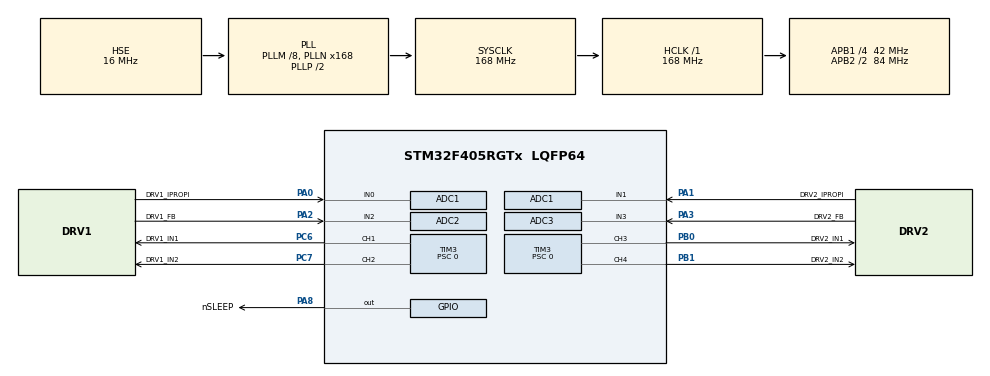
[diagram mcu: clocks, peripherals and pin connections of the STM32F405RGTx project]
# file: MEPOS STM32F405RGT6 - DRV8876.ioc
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ADC1.Channel-2\#ChannelRegularConversion=ADC_CHANNEL_0
ADC1.ClockPrescaler=ADC_CLOCK_SYNC_PCLK_DIV4
ADC1.NbrOfConversionFlag=1
ADC1.Rank-2\#ChannelRegularConversion=1
ADC1.SamplingTime-2\#ChannelRegularConversion=ADC_SAMPLETIME_3CYCLES
ADC1.master=1
ADC2.Channel-3\#ChannelRegularConversion=ADC_CHANNEL_2
ADC2.NbrOfConversionFlag=1
ADC2.Rank-3\#ChannelRegularConversion=1
ADC2.SamplingTime-3\#ChannelRegularConversion=ADC_SAMPLETIME_3CYCLES
ADC3.Channel-2\#ChannelRegularConversion=ADC_CHANNEL_3
ADC3.NbrOfConversionFlag=1
ADC3.Rank-2\#ChannelRegularConversion=1
ADC3.SamplingTime-2\#ChannelRegularConversion=ADC_SAMPLETIME_3CYCLES
Dma.ADC1.0.Direction=DMA_PERIPH_TO_MEMORY
Dma.ADC1.0.FIFOMode=DMA_FIFOMODE_DISABLE
Dma.ADC1.0.Instance=DMA2_Stream0
Dma.ADC1.0.MemDataAlignment=DMA_MDATAALIGN_HALFWORD
Dma.ADC1.0.MemInc=DMA_MINC_ENABLE
Dma.ADC1.0.Mode=DMA_CIRCULAR
Dma.ADC1.0.PeriphDataAlignment=DMA_PDATAALIGN_HALFWORD
Dma.ADC1.0.PeriphInc=DMA_PINC_DISABLE
Dma.ADC1.0.Priority=DMA_PRIORITY_LOW
Dma.ADC2.6.Direction=DMA_PERIPH_TO_MEMORY
Dma.ADC2.6.FIFOMode=DMA_FIFOMODE_DISABLE
Dma.ADC2.6.Instance=DMA2_Stream2
Dma.ADC2.6.MemDataAlignment=DMA_MDATAALIGN_HALFWORD
Dma.ADC2.6.MemInc=DMA_MINC_ENABLE
Dma.ADC2.6.Mode=DMA_CIRCULAR
Dma.ADC2.6.PeriphDataAlignment=DMA_PDATAALIGN_HALFWORD
Dma.ADC2.6.PeriphInc=DMA_PINC_DISABLE
Dma.ADC2.6.Priority=DMA_PRIORITY_LOW
Dma.ADC3.5.Direction=DMA_PERIPH_TO_MEMORY
Dma.ADC3.5.FIFOMode=DMA_FIFOMODE_DISABLE
Dma.ADC3.5.Instance=DMA2_Stream1
Dma.ADC3.5.MemDataAlignment=DMA_MDATAALIGN_HALFWORD
Dma.ADC3.5.MemInc=DMA_MINC_ENABLE
Dma.ADC3.5.Mode=DMA_CIRCULAR
Dma.ADC3.5.PeriphDataAlignment=DMA_PDATAALIGN_HALFWORD
Dma.ADC3.5.PeriphInc=DMA_PINC_DISABLE
Dma.ADC3.5.Priority=DMA_PRIORITY_LOW
Dma.Request0=ADC1
Dma.Request1=TIM3_CH1/TRIG
Dma.Request2=TIM3_CH2
Dma.Request3=TIM3_CH3
Dma.Request4=TIM3_CH4/UP
Dma.Request5=ADC3
Dma.Request6=ADC2
Dma.TIM3_CH1/TRIG.1.Direction=DMA_PERIPH_TO_MEMORY
Dma.TIM3_CH1/TRIG.1.FIFOMode=DMA_FIFOMODE_DISABLE
Dma.TIM3_CH1/TRIG.1.Instance=DMA1_Stream4
Dma.TIM3_CH1/TRIG.1.MemDataAlignment=DMA_MDATAALIGN_HALFWORD
Dma.TIM3_CH1/TRIG.1.MemInc=DMA_MINC_ENABLE
Dma.TIM3_CH1/TRIG.1.Mode=DMA_CIRCULAR
Dma.TIM3_CH1/TRIG.1.PeriphDataAlignment=DMA_PDATAALIGN_HALFWORD
Dma.TIM3_CH1/TRIG.1.PeriphInc=DMA_PINC_DISABLE
Dma.TIM3_CH1/TRIG.1.Priority=DMA_PRIORITY_LOW
Dma.TIM3_CH2.2.Direction=DMA_PERIPH_TO_MEMORY
Dma.TIM3_CH2.2.FIFOMode=DMA_FIFOMODE_DISABLE
Dma.TIM3_CH2.2.Instance=DMA1_Stream5
Dma.TIM3_CH2.2.MemDataAlignment=DMA_MDATAALIGN_HALFWORD
Dma.TIM3_CH2.2.MemInc=DMA_MINC_ENABLE
Dma.TIM3_CH2.2.Mode=DMA_CIRCULAR
Dma.TIM3_CH2.2.PeriphDataAlignment=DMA_PDATAALIGN_HALFWORD
Dma.TIM3_CH2.2.PeriphInc=DMA_PINC_DISABLE
Dma.TIM3_CH2.2.Priority=DMA_PRIORITY_LOW
Dma.TIM3_CH3.3.Direction=DMA_PERIPH_TO_MEMORY
Dma.TIM3_CH3.3.FIFOMode=DMA_FIFOMODE_DISABLE
Dma.TIM3_CH3.3.Instance=DMA1_Stream7
Dma.TIM3_CH3.3.MemDataAlignment=DMA_MDATAALIGN_HALFWORD
Dma.TIM3_CH3.3.MemInc=DMA_MINC_ENABLE
Dma.TIM3_CH3.3.Mode=DMA_CIRCULAR
Dma.TIM3_CH3.3.PeriphDataAlignment=DMA_PDATAALIGN_HALFWORD
Dma.TIM3_CH3.3.PeriphInc=DMA_PINC_DISABLE
Dma.TIM3_CH3.3.Priority=DMA_PRIORITY_LOW
Dma.TIM3_CH4/UP.4.Direction=DMA_PERIPH_TO_MEMORY
Dma.TIM3_CH4/UP.4.FIFOMode=DMA_FIFOMODE_DISABLE
Dma.TIM3_CH4/UP.4.Instance=DMA1_Stream2
Dma.TIM3_CH4/UP.4.MemDataAlignment=DMA_MDATAALIGN_HALFWORD
Dma.TIM3_CH4/UP.4.MemInc=DMA_MINC_ENABLE
Dma.TIM3_CH4/UP.4.Mode=DMA_CIRCULAR
Dma.TIM3_CH4/UP.4.PeriphDataAlignment=DMA_PDATAALIGN_HALFWORD
Dma.TIM3_CH4/UP.4.PeriphInc=DMA_PINC_DISABLE
Dma.TIM3_CH4/UP.4.Priority=DMA_PRIORITY_LOW
Mcu.Family=STM32F4
Mcu.Name=STM32F405RGTx
Mcu.Package=LQFP64
NVIC.ADC_IRQn=true\:0\:0\:false\:false\:true\:true\:true\:true
NVIC.DMA1_Stream2_IRQn=true\:0\:0\:false\:false\:true\:false\:true\:true
NVIC.DMA1_Stream4_IRQn=true\:0\:0\:false\:false\:true\:false\:true\:true
NVIC.DMA1_Stream5_IRQn=true\:0\:0\:false\:false\:true\:false\:true\:true
NVIC.DMA1_Stream7_IRQn=true\:0\:0\:false\:false\:true\:false\:true\:true
NVIC.DMA2_Stream0_IRQn=true\:0\:0\:false\:false\:true\:false\:true\:true
NVIC.DMA2_Stream1_IRQn=true\:0\:0\:false\:false\:true\:false\:true\:true
NVIC.DMA2_Stream2_IRQn=true\:0\:0\:false\:false\:true\:false\:true\:true
NVIC.PriorityGroup=NVIC_PRIORITYGROUP_4
NVIC.TIM3_IRQn=true\:0\:0\:false\:false\:true\:true\:true\:true
PA0-WKUP.GPIO_Label=DRV1_IPROPI
PA0-WKUP.Signal=ADCx_IN0
PA1.GPIO_Label=DRV2_IPROPI
PA1.Signal=ADCx_IN1
PA13.Mode=Serial_Wire
PA13.Signal=SYS_JTMS-SWDIO
PA14.Mode=Serial_Wire
PA14.Signal=SYS_JTCK-SWCLK
PA2.GPIO_Label=DRV1_FB
PA2.Signal=ADCx_IN2
PA3.GPIO_Label=DRV2_FB
PA3.Signal=ADCx_IN3
PA8.GPIO_Label=nSLEEP
PA8.Signal=GPIO_Output
PB0.GPIO_Label=DRV2_IN1
PB0.Signal=S_TIM3_CH3
PB1.GPIO_Label=DRV2_IN2
PB1.Signal=S_TIM3_CH4
PC6.GPIO_Label=DRV1_IN1
PC6.Signal=S_TIM3_CH1
PC7.GPIO_Label=DRV1_IN2
PC7.Signal=S_TIM3_CH2
PH0-OSC_IN.Mode=HSE-External-Oscillator
PH0-OSC_IN.Signal=RCC_OSC_IN
PH1-OSC_OUT.Mode=HSE-External-Oscillator
PH1-OSC_OUT.Signal=RCC_OSC_OUT
ProjectManager.HeapSize=0x200
ProjectManager.StackSize=0x400
ProjectManager.TargetToolchain=STM32CubeIDE
RCC.48MHZClocksFreq_Value=48000000
RCC.AHBFreq_Value=168000000
RCC.APB1CLKDivider=RCC_HCLK_DIV4
RCC.APB1Freq_Value=42000000
RCC.APB1TimFreq_Value=84000000
RCC.APB2CLKDivider=RCC_HCLK_DIV2
RCC.APB2Freq_Value=84000000
RCC.APB2TimFreq_Value=168000000
RCC.CortexFreq_Value=168000000
RCC.HCLKFreq_Value=168000000
RCC.HSE_VALUE=16000000
RCC.HSI_VALUE=16000000
RCC.LSE_VALUE=32768
RCC.PLLM=8
RCC.PLLN=168
RCC.PLLQ=7
RCC.PLLSourceVirtual=RCC_PLLSOURCE_HSE
RCC.SYSCLKFreq_VALUE=168000000
RCC.SYSCLKSource=RCC_SYSCLKSOURCE_PLLCLK
RCC.VCOOutputFreq_Value=336000000
SH.ADCx_IN0.0=ADC1_IN0,IN0
SH.ADCx_IN1.0=ADC1_IN1,IN1
SH.ADCx_IN2.0=ADC2_IN2,IN2
SH.ADCx_IN3.0=ADC3_IN3,IN3
SH.S_TIM3_CH1.0=TIM3_CH1,PWM Generation1 CH1
SH.S_TIM3_CH2.0=TIM3_CH2,PWM Generation2 CH2
SH.S_TIM3_CH3.0=TIM3_CH3,PWM Generation3 CH3
SH.S_TIM3_CH4.0=TIM3_CH4,PWM Generation4 CH4
TIM3.Channel-PWM\ Generation1\ CH1=TIM_CHANNEL_1
TIM3.Channel-PWM\ Generation2\ CH2=TIM_CHANNEL_2
TIM3.Channel-PWM\ Generation3\ CH3=TIM_CHANNEL_3
TIM3.Channel-PWM\ Generation4\ CH4=TIM_CHANNEL_4
TIM3.Period=8400-1
TIM3.Prescaler=0
VP_TIM3_VS_ClockSourceINT.Mode=Internal
board=custom

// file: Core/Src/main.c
/* USER CODE BEGIN Header */
/**
  ******************************************************************************
  * @file           : main.c
  * @brief          : Main program body
  ******************************************************************************
  * @attention
  *
  * Copyright (c) 2022 STMicroelectronics.
  * All rights reserved.
  *
  * This software is licensed under terms that can be found in the LICENSE file
  * in the root directory of this software component.
  * If no LICENSE file comes with this software, it is provided AS-IS.
  *
  ******************************************************************************
  */
/* USER CODE END Header */
#include "main.h"

/* USER CODE BEGIN Includes */
#include "DRV8876.h"

/* USER CODE END Includes */

ADC_HandleTypeDef hadc1;
ADC_HandleTypeDef hadc2;
ADC_HandleTypeDef hadc3;
DMA_HandleTypeDef hdma_adc1;
DMA_HandleTypeDef hdma_adc2;
DMA_HandleTypeDef hdma_adc3;

TIM_HandleTypeDef htim3;
DMA_HandleTypeDef hdma_tim3_ch1_trig;
DMA_HandleTypeDef hdma_tim3_ch2;
DMA_HandleTypeDef hdma_tim3_ch3;
DMA_HandleTypeDef hdma_tim3_ch4_up;

/* USER CODE BEGIN PV */
DRV8876_TypeDef xAxis;
DRV8876_TypeDef yAxis;

/* USER CODE END PV */

void SystemClock_Config(void);
static void MX_GPIO_Init(void);
static void MX_DMA_Init(void);
static void MX_ADC1_Init(void);
static void MX_ADC2_Init(void);
static void MX_TIM3_Init(void);
static void MX_ADC3_Init(void);

int main(void)
{

  /* MCU Configuration--------------------------------------------------------*/

  /* Reset of all peripherals, Initializes the Flash interface and the Systick. */
  HAL_Init();

  /* Configure the system clock */
  SystemClock_Config();

  /* Initialize all configured peripherals */
  MX_GPIO_Init();
  MX_DMA_Init();
  MX_ADC1_Init();
  MX_ADC2_Init();
  MX_TIM3_Init();
  MX_ADC3_Init();
  /* USER CODE BEGIN 2 */
  Init_DRV8876(&xAxis, &hadc2, &hadc1, &htim3, TIM_CHANNEL_1, TIM_CHANNEL_2);
  Init_DRV8876(&yAxis, &hadc3, &hadc1, &htim3, TIM_CHANNEL_3, TIM_CHANNEL_4);

  Start_DRV8876(&xAxis);
  Start_DRV8876(&yAxis);

  /* USER CODE END 2 */

  /* Infinite loop */
  while (1)
  {

  }
}

void SystemClock_Config(void)
{
  RCC_OscInitTypeDef RCC_OscInitStruct = {0};
  RCC_ClkInitTypeDef RCC_ClkInitStruct = {0};

  /** Configure the main internal regulator output voltage
  */
  __HAL_RCC_PWR_CLK_ENABLE();
  __HAL_PWR_VOLTAGESCALING_CONFIG(PWR_REGULATOR_VOLTAGE_SCALE1);

  /** Initializes the RCC Oscillators according to the specified parameters
  * in the RCC_OscInitTypeDef structure.
  */
  RCC_OscInitStruct.OscillatorType = RCC_OSCILLATORTYPE_HSE;
  RCC_OscInitStruct.HSEState = RCC_HSE_ON;
  RCC_OscInitStruct.PLL.PLLState = RCC_PLL_ON;
  RCC_OscInitStruct.PLL.PLLSource = RCC_PLLSOURCE_HSE;
  RCC_OscInitStruct.PLL.PLLM = 8;
  RCC_OscInitStruct.PLL.PLLN = 168;
  RCC_OscInitStruct.PLL.PLLP = RCC_PLLP_DIV2;
  RCC_OscInitStruct.PLL.PLLQ = 7;
  if (HAL_RCC_OscConfig(&RCC_OscInitStruct) != HAL_OK)
  {
    Error_Handler();
  }

  /** Initializes the CPU, AHB and APB buses clocks
  */
  RCC_ClkInitStruct.ClockType = RCC_CLOCKTYPE_HCLK|RCC_CLOCKTYPE_SYSCLK
                              |RCC_CLOCKTYPE_PCLK1|RCC_CLOCKTYPE_PCLK2;
  RCC_ClkInitStruct.SYSCLKSource = RCC_SYSCLKSOURCE_PLLCLK;
  RCC_ClkInitStruct.AHBCLKDivider = RCC_SYSCLK_DIV1;
  RCC_ClkInitStruct.APB1CLKDivider = RCC_HCLK_DIV4;
  RCC_ClkInitStruct.APB2CLKDivider = RCC_HCLK_DIV2;

  if (HAL_RCC_ClockConfig(&RCC_ClkInitStruct, FLASH_LATENCY_5) != HAL_OK)
  {
    Error_Handler();
  }
}

static void MX_ADC1_Init(void)
{

  ADC_ChannelConfTypeDef sConfig = {0};

  /** Configure the global features of the ADC (Clock, Resolution, Data Alignment and number of conversion)
  */
  hadc1.Instance = ADC1;
  hadc1.Init.ClockPrescaler = ADC_CLOCK_SYNC_PCLK_DIV4;
  hadc1.Init.Resolution = ADC_RESOLUTION_12B;
  hadc1.Init.ScanConvMode = DISABLE;
  hadc1.Init.ContinuousConvMode = DISABLE;
  hadc1.Init.DiscontinuousConvMode = DISABLE;
  hadc1.Init.ExternalTrigConvEdge = ADC_EXTERNALTRIGCONVEDGE_NONE;
  hadc1.Init.ExternalTrigConv = ADC_SOFTWARE_START;
  hadc1.Init.DataAlign = ADC_DATAALIGN_RIGHT;
  hadc1.Init.NbrOfConversion = 1;
  hadc1.Init.DMAContinuousRequests = DISABLE;
  hadc1.Init.EOCSelection = ADC_EOC_SINGLE_CONV;
  if (HAL_ADC_Init(&hadc1) != HAL_OK)
  {
    Error_Handler();
  }

  /** Configure for the selected ADC regular channel its corresponding rank in the sequencer and its sample time.
  */
  sConfig.Channel = ADC_CHANNEL_0;
  sConfig.Rank = 1;
  sConfig.SamplingTime = ADC_SAMPLETIME_3CYCLES;
  if (HAL_ADC_ConfigChannel(&hadc1, &sConfig) != HAL_OK)
  {
    Error_Handler();
  }

}

static void MX_ADC2_Init(void)
{

  ADC_ChannelConfTypeDef sConfig = {0};

  /** Configure the global features of the ADC (Clock, Resolution, Data Alignment and number of conversion)
  */
  hadc2.Instance = ADC2;
  hadc2.Init.ClockPrescaler = ADC_CLOCK_SYNC_PCLK_DIV4;
  hadc2.Init.Resolution = ADC_RESOLUTION_12B;
  hadc2.Init.ScanConvMode = DISABLE;
  hadc2.Init.ContinuousConvMode = DISABLE;
  hadc2.Init.DiscontinuousConvMode = DISABLE;
  hadc2.Init.ExternalTrigConvEdge = ADC_EXTERNALTRIGCONVEDGE_NONE;
  hadc2.Init.ExternalTrigConv = ADC_SOFTWARE_START;
  hadc2.Init.DataAlign = ADC_DATAALIGN_RIGHT;
  hadc2.Init.NbrOfConversion = 1;
  hadc2.Init.DMAContinuousRequests = DISABLE;
  hadc2.Init.EOCSelection = ADC_EOC_SINGLE_CONV;
  if (HAL_ADC_Init(&hadc2) != HAL_OK)
  {
    Error_Handler();
  }

  /** Configure for the selected ADC regular channel its corresponding rank in the sequencer and its sample time.
  */
  sConfig.Channel = ADC_CHANNEL_2;
  sConfig.Rank = 1;
  sConfig.SamplingTime = ADC_SAMPLETIME_3CYCLES;
  if (HAL_ADC_ConfigChannel(&hadc2, &sConfig) != HAL_OK)
  {
    Error_Handler();
  }

}

static void MX_ADC3_Init(void)
{

  ADC_ChannelConfTypeDef sConfig = {0};

  /** Configure the global features of the ADC (Clock, Resolution, Data Alignment and number of conversion)
  */
  hadc3.Instance = ADC3;
  hadc3.Init.ClockPrescaler = ADC_CLOCK_SYNC_PCLK_DIV4;
  hadc3.Init.Resolution = ADC_RESOLUTION_12B;
  hadc3.Init.ScanConvMode = DISABLE;
  hadc3.Init.ContinuousConvMode = DISABLE;
  hadc3.Init.DiscontinuousConvMode = DISABLE;
  hadc3.Init.ExternalTrigConvEdge = ADC_EXTERNALTRIGCONVEDGE_NONE;
  hadc3.Init.ExternalTrigConv = ADC_SOFTWARE_START;
  hadc3.Init.DataAlign = ADC_DATAALIGN_RIGHT;
  hadc3.Init.NbrOfConversion = 1;
  hadc3.Init.DMAContinuousRequests = DISABLE;
  hadc3.Init.EOCSelection = ADC_EOC_SINGLE_CONV;
  if (HAL_ADC_Init(&hadc3) != HAL_OK)
  {
    Error_Handler();
  }

  /** Configure for the selected ADC regular channel its corresponding rank in the sequencer and its sample time.
  */
  sConfig.Channel = ADC_CHANNEL_3;
  sConfig.Rank = 1;
  sConfig.SamplingTime = ADC_SAMPLETIME_3CYCLES;
  if (HAL_ADC_ConfigChannel(&hadc3, &sConfig) != HAL_OK)
  {
    Error_Handler();
  }

}

static void MX_TIM3_Init(void)
{

  TIM_ClockConfigTypeDef sClockSourceConfig = {0};
  TIM_MasterConfigTypeDef sMasterConfig = {0};
  TIM_OC_InitTypeDef sConfigOC = {0};

  htim3.Instance = TIM3;
  htim3.Init.Prescaler = 0;
  htim3.Init.CounterMode = TIM_COUNTERMODE_UP;
  htim3.Init.Period = 8400-1;
  htim3.Init.ClockDivision = TIM_CLOCKDIVISION_DIV1;
  htim3.Init.AutoReloadPreload = TIM_AUTORELOAD_PRELOAD_DISABLE;
  if (HAL_TIM_Base_Init(&htim3) != HAL_OK)
  {
    Error_Handler();
  }
  sClockSourceConfig.ClockSource = TIM_CLOCKSOURCE_INTERNAL;
  if (HAL_TIM_ConfigClockSource(&htim3, &sClockSourceConfig) != HAL_OK)
  {
    Error_Handler();
  }
  if (HAL_TIM_PWM_Init(&htim3) != HAL_OK)
  {
    Error_Handler();
  }
  sMasterConfig.MasterOutputTrigger = TIM_TRGO_RESET;
  sMasterConfig.MasterSlaveMode = TIM_MASTERSLAVEMODE_DISABLE;
  if (HAL_TIMEx_MasterConfigSynchronization(&htim3, &sMasterConfig) != HAL_OK)
  {
    Error_Handler();
  }
  sConfigOC.OCMode = TIM_OCMODE_PWM1;
  sConfigOC.Pulse = 0;
  sConfigOC.OCPolarity = TIM_OCPOLARITY_HIGH;
  sConfigOC.OCFastMode = TIM_OCFAST_DISABLE;
  if (HAL_TIM_PWM_ConfigChannel(&htim3, &sConfigOC, TIM_CHANNEL_1) != HAL_OK)
  {
    Error_Handler();
  }
  if (HAL_TIM_PWM_ConfigChannel(&htim3, &sConfigOC, TIM_CHANNEL_2) != HAL_OK)
  {
    Error_Handler();
  }
  if (HAL_TIM_PWM_ConfigChannel(&htim3, &sConfigOC, TIM_CHANNEL_3) != HAL_OK)
  {
    Error_Handler();
  }
  if (HAL_TIM_PWM_ConfigChannel(&htim3, &sConfigOC, TIM_CHANNEL_4) != HAL_OK)
  {
    Error_Handler();
  }
  HAL_TIM_MspPostInit(&htim3);

}

static void MX_DMA_Init(void)
{

  /* DMA controller clock enable */
  __HAL_RCC_DMA2_CLK_ENABLE();
  __HAL_RCC_DMA1_CLK_ENABLE();

  /* DMA interrupt init */
  /* DMA1_Stream2_IRQn interrupt configuration */
  HAL_NVIC_SetPriority(DMA1_Stream2_IRQn, 0, 0);
  HAL_NVIC_EnableIRQ(DMA1_Stream2_IRQn);
  /* DMA1_Stream4_IRQn interrupt configuration */
  HAL_NVIC_SetPriority(DMA1_Stream4_IRQn, 0, 0);
  HAL_NVIC_EnableIRQ(DMA1_Stream4_IRQn);
  /* DMA1_Stream5_IRQn interrupt configuration */
  HAL_NVIC_SetPriority(DMA1_Stream5_IRQn, 0, 0);
  HAL_NVIC_EnableIRQ(DMA1_Stream5_IRQn);
  /* DMA1_Stream7_IRQn interrupt configuration */
  HAL_NVIC_SetPriority(DMA1_Stream7_IRQn, 0, 0);
  HAL_NVIC_EnableIRQ(DMA1_Stream7_IRQn);
  /* DMA2_Stream0_IRQn interrupt configuration */
  HAL_NVIC_SetPriority(DMA2_Stream0_IRQn, 0, 0);
  HAL_NVIC_EnableIRQ(DMA2_Stream0_IRQn);
  /* DMA2_Stream1_IRQn interrupt configuration */
  HAL_NVIC_SetPriority(DMA2_Stream1_IRQn, 0, 0);
  HAL_NVIC_EnableIRQ(DMA2_Stream1_IRQn);
  /* DMA2_Stream2_IRQn interrupt configuration */
  HAL_NVIC_SetPriority(DMA2_Stream2_IRQn, 0, 0);
  HAL_NVIC_EnableIRQ(DMA2_Stream2_IRQn);

}

static void MX_GPIO_Init(void)
{
  GPIO_InitTypeDef GPIO_InitStruct = {0};

  /* GPIO Ports Clock Enable */
  __HAL_RCC_GPIOH_CLK_ENABLE();
  __HAL_RCC_GPIOA_CLK_ENABLE();
  __HAL_RCC_GPIOB_CLK_ENABLE();
  __HAL_RCC_GPIOC_CLK_ENABLE();

  /*Configure GPIO pin Output Level */
  HAL_GPIO_WritePin(nSLEEP_GPIO_Port, nSLEEP_Pin, GPIO_PIN_RESET);

  /*Configure GPIO pin : nSLEEP_Pin */
  GPIO_InitStruct.Pin = nSLEEP_Pin;
  GPIO_InitStruct.Mode = GPIO_MODE_OUTPUT_PP;
  GPIO_InitStruct.Pull = GPIO_NOPULL;
  GPIO_InitStruct.Speed = GPIO_SPEED_FREQ_LOW;
  HAL_GPIO_Init(nSLEEP_GPIO_Port, &GPIO_InitStruct);

}

void Error_Handler(void)
{
  __disable_irq();
  while (1)
  {
  }
}
